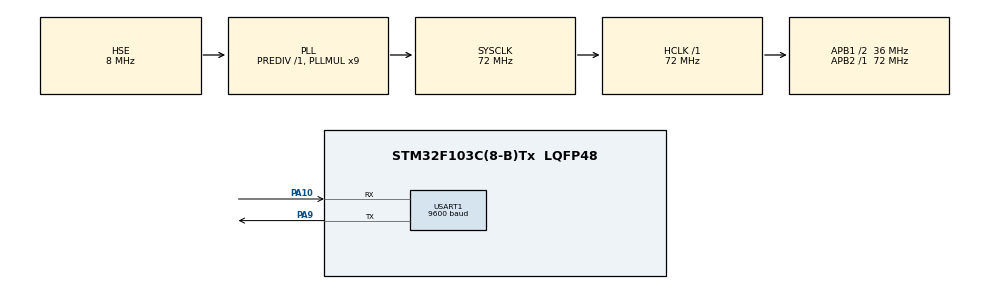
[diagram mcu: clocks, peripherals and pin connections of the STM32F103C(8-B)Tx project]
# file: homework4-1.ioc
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Mcu.Family=STM32F1
Mcu.Name=STM32F103C(8-B)Tx
Mcu.Package=LQFP48
NVIC.PriorityGroup=NVIC_PRIORITYGROUP_4
NVIC.USART1_IRQn=true\:0\:0\:false\:false\:true\:true\:true\:true
PA10.Mode=Asynchronous
PA10.Signal=USART1_RX
PA13.Mode=Serial_Wire
PA13.Signal=SYS_JTMS-SWDIO
PA14.Mode=Serial_Wire
PA14.Signal=SYS_JTCK-SWCLK
PA9.Mode=Asynchronous
PA9.Signal=USART1_TX
PD0-OSC_IN.Mode=HSE-External-Oscillator
PD0-OSC_IN.Signal=RCC_OSC_IN
PD1-OSC_OUT.Mode=HSE-External-Oscillator
PD1-OSC_OUT.Signal=RCC_OSC_OUT
ProjectManager.HeapSize=0x200
ProjectManager.StackSize=0x400
ProjectManager.TargetToolchain=CMake
RCC.AHBFreq_Value=72000000
RCC.APB1CLKDivider=RCC_HCLK_DIV2
RCC.APB1Freq_Value=36000000
RCC.APB1TimFreq_Value=72000000
RCC.APB2Freq_Value=72000000
RCC.APB2TimFreq_Value=72000000
RCC.HCLKFreq_Value=72000000
RCC.PLLMUL=RCC_PLL_MUL9
RCC.PLLSourceVirtual=RCC_PLLSOURCE_HSE
RCC.SYSCLKFreq_VALUE=72000000
RCC.SYSCLKSource=RCC_SYSCLKSOURCE_PLLCLK
RCC.USBFreq_Value=72000000
USART1.BaudRate=9600
USART1.VirtualMode=VM_ASYNC
board=custom

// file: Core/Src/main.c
/* USER CODE BEGIN Header */
/**
  ******************************************************************************
  * @file           : main.c
  * @brief          : Main program body
  ******************************************************************************
  * @attention
  *
  * Copyright (c) 2026 STMicroelectronics.
  * All rights reserved.
  *
  * This software is licensed under terms that can be found in the LICENSE file
  * in the root directory of this software component.
  * If no LICENSE file comes with this software, it is provided AS-IS.
  *
  ******************************************************************************
  */
/* USER CODE END Header */
#include "main.h"
#include "stm32f1xx_hal_uart.h"
#include <stdint.h>
#include <string.h>

UART_HandleTypeDef huart1;

/* USER CODE BEGIN PV */
uint32_t x = 0;
uint32_t y = 0;
uint32_t z = 0;
uint16_t calculated_crc;
uint16_t received_crc;
uint8_t frame[17];
uint8_t rxdate;//接收开关指令
volatile int state=0;
volatile uint8_t is_transmitting = 0; //是否正在发送数据帧
/* USER CODE END PV */

void SystemClock_Config(void);
static void MX_GPIO_Init(void);
static void MX_USART1_UART_Init(void);

/* USER CODE BEGIN 0 */
/*计算crc的算法，用于根据前面的数据计算crc16，并且与接收到的crc进行比较*/
uint16_t CRC_MODBUS(uint8_t *data, uint16_t length)
{
  uint16_t crc = 0xFFFF;
  for (uint16_t i = 0; i < length; i++)
  {
    crc ^= data[i];
    for (uint8_t j = 0; j < 8; j++)
    {
      if (crc & 0x0001)
      {
        crc >>= 1;
        crc ^= 0xA001;
      }
      else
      {
        crc >>= 1;
      }
    }
  }
  return crc;

}

//发送数据帧的函数，用于将x、y、z的值打包成数据帧，并计算对应的crc16，然后通过串口发送出去
void Send_Data_Frame(void)
{
    if(is_transmitting==1) {
      //如果忙碌就不发送
        return;
    }

    uint16_t crc;

    frame[0] = 0x5A;
    frame[1] = 0xA5;
    frame[2] = 0x01;

    //用大端序发送数据
    frame[6] = (uint8_t)(x & 0xFF);
    frame[5] = (uint8_t)((x >> 8) & 0xFF);
    frame[4] = (uint8_t)((x >> 16) & 0xFF);
    frame[3] = (uint8_t)((x >> 24) & 0xFF);

    frame[10] = (uint8_t)(y & 0xFF);
    frame[9] = (uint8_t)((y >> 8) & 0xFF);
    frame[8] = (uint8_t)((y >> 16) & 0xFF);
    frame[7] = (uint8_t)((y >> 24) & 0xFF);

    frame[14] = (uint8_t)(z & 0xFF);
    frame[13] = (uint8_t)((z >> 8) & 0xFF);
    frame[12] = (uint8_t)((z >> 16) & 0xFF);
    frame[11] = (uint8_t)((z >> 24) & 0xFF);

    crc= CRC_MODBUS(frame, 15);
    frame[15] = (uint8_t)(crc & 0xFF);
    frame[16] = (uint8_t)((crc >> 8) & 0xFF);

    is_transmitting = 1;
    HAL_UART_Transmit_IT(&huart1, frame, 17);
}

void HAL_UART_TxCpltCallback(UART_HandleTypeDef *huart)
{
    if (huart == &huart1)
    {
        is_transmitting = 0; //发送完成，清除忙碌标志
    }
}

void HAL_UART_RxCpltCallback(UART_HandleTypeDef *huart)
{
  if (huart == &huart1)
  {
    if(rxdate==0x00)//开启命令
    {
      state=1;
    }
    else if(rxdate==0x01)//停止命令
    {
      state=0;
    }
    HAL_UART_Receive_IT(&huart1, &rxdate, 1);
  }
}
/* USER CODE END 0 */

int main(void)
{

  /* MCU Configuration--------------------------------------------------------*/

  /* Reset of all peripherals, Initializes the Flash interface and the Systick. */
  HAL_Init();

  /* Configure the system clock */
  SystemClock_Config();

  /* Initialize all configured peripherals */
  MX_GPIO_Init();
  MX_USART1_UART_Init();
  /* USER CODE BEGIN 2 */
  HAL_UART_Receive_IT(&huart1, &rxdate, 1);
  uint32_t pastedtime;
  pastedtime = HAL_GetTick();

  /* USER CODE END 2 */

  /* Infinite loop */
  /* USER CODE BEGIN WHILE */
  while (1)
  {
    if(HAL_GetTick() - pastedtime >= 20)
    {
      pastedtime += 20;

      HAL_Delay(5);
      x++;
      y++;
      z++;

      if(state==1){

        Send_Data_Frame();
      }
    }

    /* USER CODE END WHILE */

  }
}

void SystemClock_Config(void)
{
  RCC_OscInitTypeDef RCC_OscInitStruct = {0};
  RCC_ClkInitTypeDef RCC_ClkInitStruct = {0};

  /** Initializes the RCC Oscillators according to the specified parameters
  * in the RCC_OscInitTypeDef structure.
  */
  RCC_OscInitStruct.OscillatorType = RCC_OSCILLATORTYPE_HSE;
  RCC_OscInitStruct.HSEState = RCC_HSE_ON;
  RCC_OscInitStruct.HSEPredivValue = RCC_HSE_PREDIV_DIV1;
  RCC_OscInitStruct.HSIState = RCC_HSI_ON;
  RCC_OscInitStruct.PLL.PLLState = RCC_PLL_ON;
  RCC_OscInitStruct.PLL.PLLSource = RCC_PLLSOURCE_HSE;
  RCC_OscInitStruct.PLL.PLLMUL = RCC_PLL_MUL9;
  if (HAL_RCC_OscConfig(&RCC_OscInitStruct) != HAL_OK)
  {
    Error_Handler();
  }

  /** Initializes the CPU, AHB and APB buses clocks
  */
  RCC_ClkInitStruct.ClockType = RCC_CLOCKTYPE_HCLK|RCC_CLOCKTYPE_SYSCLK
                              |RCC_CLOCKTYPE_PCLK1|RCC_CLOCKTYPE_PCLK2;
  RCC_ClkInitStruct.SYSCLKSource = RCC_SYSCLKSOURCE_PLLCLK;
  RCC_ClkInitStruct.AHBCLKDivider = RCC_SYSCLK_DIV1;
  RCC_ClkInitStruct.APB1CLKDivider = RCC_HCLK_DIV2;
  RCC_ClkInitStruct.APB2CLKDivider = RCC_HCLK_DIV1;

  if (HAL_RCC_ClockConfig(&RCC_ClkInitStruct, FLASH_LATENCY_2) != HAL_OK)
  {
    Error_Handler();
  }
}

static void MX_USART1_UART_Init(void)
{

  huart1.Instance = USART1;
  huart1.Init.BaudRate = 9600;
  huart1.Init.WordLength = UART_WORDLENGTH_8B;
  huart1.Init.StopBits = UART_STOPBITS_1;
  huart1.Init.Parity = UART_PARITY_NONE;
  huart1.Init.Mode = UART_MODE_TX_RX;
  huart1.Init.HwFlowCtl = UART_HWCONTROL_NONE;
  huart1.Init.OverSampling = UART_OVERSAMPLING_16;
  if (HAL_UART_Init(&huart1) != HAL_OK)
  {
    Error_Handler();
  }

}

static void MX_GPIO_Init(void)
{

  /* GPIO Ports Clock Enable */
  __HAL_RCC_GPIOD_CLK_ENABLE();
  __HAL_RCC_GPIOA_CLK_ENABLE();

}

void Error_Handler(void)
{
  __disable_irq();
  while (1)
  {
  }
}
